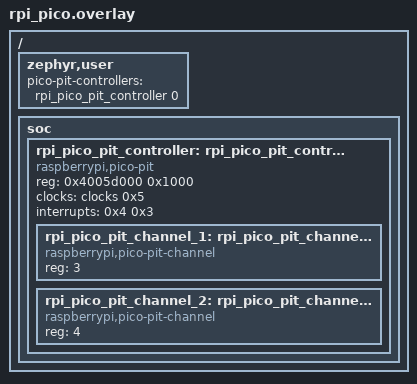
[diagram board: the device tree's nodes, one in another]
/*
 * Copyright (c) 2024 Navimatix GmbH
 *
 * SPDX-License-Identifier: Apache-2.0
 */

/ {
	zephyr,user {
		pico-pit-controllers = <&rpi_pico_pit_controller 0>;
	};
};

/ {
	soc {
		rpi_pico_pit_controller: rpi_pico_pit_controller@4005d000 {
			status = "okay";
			compatible = "raspberrypi,pico-pit";
			reg = <0x4005d000 0x1000>;
			clocks = <&clocks 0x5>;
			interrupts = <0x4 0x3>;
			interrupt-names = "PWM_IRQ_WRAP";
			#pico-pit-controller-cells = <0>;
			#address-cells = <1>;
			#size-cells = <0>;

			rpi_pico_pit_channel_1: rpi_pico_pit_channel@3 {
				status = "okay";
				compatible = "raspberrypi,pico-pit-channel";
				reg = <3>;

				#pico-pit-channel-cells = <0>;
			};

			rpi_pico_pit_channel_2: rpi_pico_pit_channel@4 {
				status = "okay";
				compatible = "raspberrypi,pico-pit-channel";
				reg = <4>;

				#pico-pit-channel-cells = <0>;
			};
		};
	};
};
